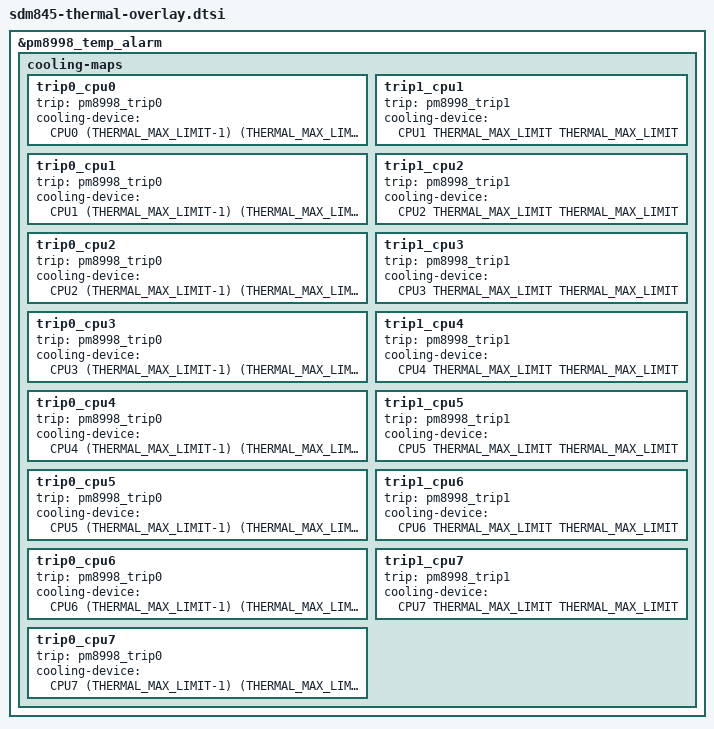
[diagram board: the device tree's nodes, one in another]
// SPDX-License-Identifier: GPL-2.0-only
/*
 * Copyright (c) 2025, Pavel Dubrova <pashadubrova@gmail.com>
 */

#include <dt-bindings/thermal/thermal.h>

&pm8998_temp_alarm {
	cooling-maps {
		trip0_cpu0 {
			trip = <&pm8998_trip0>;
			cooling-device =
				<&CPU0 (THERMAL_MAX_LIMIT-1)
					(THERMAL_MAX_LIMIT-1)>;
		};
		trip0_cpu1 {
			trip = <&pm8998_trip0>;
			cooling-device =
				<&CPU1 (THERMAL_MAX_LIMIT-1)
					(THERMAL_MAX_LIMIT-1)>;
		};
		trip0_cpu2 {
			trip = <&pm8998_trip0>;
			cooling-device =
				<&CPU2 (THERMAL_MAX_LIMIT-1)
					(THERMAL_MAX_LIMIT-1)>;
		};
		trip0_cpu3 {
			trip = <&pm8998_trip0>;
			cooling-device =
				<&CPU3 (THERMAL_MAX_LIMIT-1)
					(THERMAL_MAX_LIMIT-1)>;
		};
		trip0_cpu4 {
			trip = <&pm8998_trip0>;
			cooling-device =
				<&CPU4 (THERMAL_MAX_LIMIT-1)
					(THERMAL_MAX_LIMIT-1)>;
		};
		trip0_cpu5 {
			trip = <&pm8998_trip0>;
			cooling-device =
				<&CPU5 (THERMAL_MAX_LIMIT-1)
					(THERMAL_MAX_LIMIT-1)>;
		};
		trip0_cpu6 {
			trip = <&pm8998_trip0>;
			cooling-device =
				<&CPU6 (THERMAL_MAX_LIMIT-1)
					(THERMAL_MAX_LIMIT-1)>;
		};
		trip0_cpu7 {
			trip = <&pm8998_trip0>;
			cooling-device =
				<&CPU7 (THERMAL_MAX_LIMIT-1)
					(THERMAL_MAX_LIMIT-1)>;
		};
		trip1_cpu1 {
			trip = <&pm8998_trip1>;
			cooling-device =
				<&CPU1 THERMAL_MAX_LIMIT THERMAL_MAX_LIMIT>;
		};
		trip1_cpu2 {
			trip = <&pm8998_trip1>;
			cooling-device =
				<&CPU2 THERMAL_MAX_LIMIT THERMAL_MAX_LIMIT>;
		};
		trip1_cpu3 {
			trip = <&pm8998_trip1>;
			cooling-device =
				<&CPU3 THERMAL_MAX_LIMIT THERMAL_MAX_LIMIT>;
		};
		trip1_cpu4 {
			trip = <&pm8998_trip1>;
			cooling-device =
				<&CPU4 THERMAL_MAX_LIMIT THERMAL_MAX_LIMIT>;
		};
		trip1_cpu5 {
			trip = <&pm8998_trip1>;
			cooling-device =
				<&CPU5 THERMAL_MAX_LIMIT THERMAL_MAX_LIMIT>;
		};
		trip1_cpu6 {
			trip = <&pm8998_trip1>;
			cooling-device =
				<&CPU6 THERMAL_MAX_LIMIT THERMAL_MAX_LIMIT>;
		};
		trip1_cpu7 {
			trip = <&pm8998_trip1>;
			cooling-device =
				<&CPU7 THERMAL_MAX_LIMIT THERMAL_MAX_LIMIT>;
		};
	};
};
